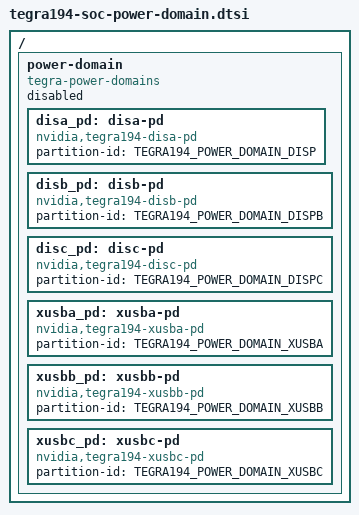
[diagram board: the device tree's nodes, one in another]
/*
 * Copyright (c) 2020, NVIDIA CORPORATION.  All rights reserved.
 *
 * This program is free software; you can redistribute it and/or modify it
 * under the terms and conditions of the GNU General Public License,
 * version 2, as published by the Free Software Foundation.
 *
 * This program is distributed in the hope it will be useful, but WITHOUT
 * ANY WARRANTY; without even the implied warranty of MERCHANTABILITY or
 * FITNESS FOR A PARTICULAR PURPOSE.  See the GNU General Public License for
 * more details.
 *
 * You should have received a copy of the GNU General Public License
 * along with this program.  If not, see <http://www.gnu.org/licenses/>.
 */

/ {
       power-domain {
               compatible = "tegra-power-domains";
               status = "disabled";

               disa_pd: disa-pd {
                       compatible = "nvidia,tegra194-disa-pd";
                       #power-domain-cells = <0>;
                       partition-id = <TEGRA194_POWER_DOMAIN_DISP>;
               };

               disb_pd: disb-pd {
                       compatible = "nvidia,tegra194-disb-pd";
                       #power-domain-cells = <0>;
                       partition-id = <TEGRA194_POWER_DOMAIN_DISPB>;
               };

               disc_pd: disc-pd {
                       compatible = "nvidia,tegra194-disc-pd";
                       #power-domain-cells = <0>;
                       partition-id = <TEGRA194_POWER_DOMAIN_DISPC>;
               };

               xusba_pd: xusba-pd {
                       compatible = "nvidia,tegra194-xusba-pd";
                       #power-domain-cells = <0>;
                       partition-id = <TEGRA194_POWER_DOMAIN_XUSBA>;
               };

               xusbb_pd: xusbb-pd {
                       compatible = "nvidia,tegra194-xusbb-pd";
                       #power-domain-cells = <0>;
                       partition-id = <TEGRA194_POWER_DOMAIN_XUSBB>;
               };

               xusbc_pd: xusbc-pd {
                       compatible = "nvidia,tegra194-xusbc-pd";
                       #power-domain-cells = <0>;
                       partition-id = <TEGRA194_POWER_DOMAIN_XUSBC>;
               };
       };
};
